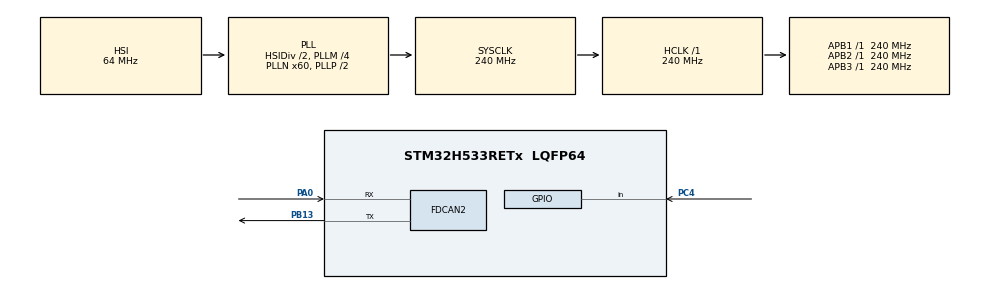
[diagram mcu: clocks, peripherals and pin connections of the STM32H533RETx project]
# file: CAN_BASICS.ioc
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BOOTPATH.BootPathName=LEGACY
BOOTPATH.UserSelectedBootPath=LEGACY
CORTEX_M33_NS.userName=CORTEX_M33
FDCAN2.CalculateBaudRateNominal=1000000
FDCAN2.CalculateTimeBitNominal=1000
FDCAN2.CalculateTimeQuantumNominal=100.0
FDCAN2.DataSyncJumpWidth=9
FDCAN2.DataTimeSeg1=10
FDCAN2.DataTimeSeg2=9
FDCAN2.FrameFormat=FDCAN_FRAME_FD_BRS
FDCAN2.NominalPrescaler=4
FDCAN2.NominalSyncJumpWidth=2
FDCAN2.NominalTimeSeg1=7
FDCAN2.NominalTimeSeg2=2
Mcu.Family=STM32H5
Mcu.Name=STM32H533RETx
Mcu.Package=LQFP64
NVIC.FDCAN2_IT0_IRQn=true\:0\:0\:false\:false\:true\:true\:true\:true
NVIC.PriorityGroup=NVIC_PRIORITYGROUP_4
PA0.Mode=FDCAN_Activate
PA0.Signal=FDCAN2_RX
PA13(JTMS/SWDIO).GPIO_Label=SWDIO
PA13(JTMS/SWDIO).Signal=DEBUG_JTMS-SWDIO
PA14(JTCK/SWCLK).GPIO_Label=SWCLK
PA14(JTCK/SWCLK).Signal=DEBUG_JTCK-SWCLK
PA15(JTDI).GPIO_Label=JTDI
PA15(JTDI).Signal=DEBUG_JTDI
PB13.Mode=FDCAN_Activate
PB13.Signal=FDCAN2_TX
PB3(JTDO/TRACESWO).GPIO_Label=SWO
PB3(JTDO/TRACESWO).Signal=DEBUG_JTDO-SWO
PC4.Signal=GPIO_Input
ProjectManager.HeapSize=0x200
ProjectManager.StackSize=0x400
ProjectManager.TargetToolchain=STM32CubeIDE
RCC.ADCFreq_Value=240000000
RCC.AHBFreq_Value=240000000
RCC.APB1Freq_Value=240000000
RCC.APB1TimFreq_Value=240000000
RCC.APB2Freq_Value=240000000
RCC.APB2TimFreq_Value=240000000
RCC.APB3Freq_Value=240000000
RCC.CSI_VALUE=4000000
RCC.CortexFreq_Value=240000000
RCC.EPOD_VALUE=32000000
RCC.FDCANClockSelection=RCC_FDCANCLKSOURCE_PLL1Q
RCC.HCLKFreq_Value=240000000
RCC.HSE_VALUE=25000000
RCC.HSI48_VALUE=48000000
RCC.HSI_VALUE=64000000
RCC.LSE_VALUE=32768
RCC.LSIRC_VALUE=32000
RCC.PLL1Q=12
RCC.PLLFRACN=0
RCC.PLLM=4
RCC.PLLN=60
RCC.PLLSourceVirtual=RCC_PLL1_SOURCE_HSI
RCC.SYSCLKFreq_VALUE=240000000
RCC.SYSCLKSource=RCC_SYSCLKSOURCE_PLLCLK
RCC.USBFreq_Value=48000000
RCC.VCOOutputFreq_Value=480000000
VP_BOOTPATH_VS_BOOTPATH.Mode=BP_Activate
VP_CORTEX_M33_NS_VS_Hclk.Mode=Hclk_Mode
VP_MEMORYMAP_VS_MEMORYMAP.Mode=CurAppReg
VP_PWR_VS_LPOM.Mode=PowerOptimisation
VP_PWR_VS_SECSignals.Mode=Security/Privilege
board=NUCLEO-H533RE

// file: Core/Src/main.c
/* USER CODE BEGIN Header */
/**
 ******************************************************************************
 * @file           : main.c
 * @brief          : Main program body
 ******************************************************************************
 * @attention
 *
 * Copyright (c) 2025 STMicroelectronics.
 * All rights reserved.
 *
 * This software is licensed under terms that can be found in the LICENSE file
 * in the root directory of this software component.
 * If no LICENSE file comes with this software, it is provided AS-IS.
 *
 ******************************************************************************
 */
/* USER CODE END Header */
#include "main.h"

/* USER CODE BEGIN Includes */
#include "string.h"
/* USER CODE END Includes */

FDCAN_HandleTypeDef hfdcan2;

/* USER CODE BEGIN PV */
FDCAN_TxHeaderTypeDef TxHeader;
FDCAN_RxHeaderTypeDef RxHeader;
uint8_t txMessageData[64];
uint8_t rxMessageData[64];
uint32_t messageID;
int receivedFrame = 0;
enum Message {
	VCUMaybe, VCUERROR1, VCUREADY
};
/* USER CODE END PV */

void SystemClock_Config(void);
static void MX_GPIO_Init(void);
static void MX_FDCAN2_Init(void);
/* USER CODE BEGIN PFP */
void startupFDCAN(FDCAN_HandleTypeDef *hfdcan, FDCAN_TxHeaderTypeDef *tx_header,
		void (*err_handler)(void));
/* USER CODE END PFP */

int main(void)
{

  /* MCU Configuration--------------------------------------------------------*/

  /* Reset of all peripherals, Initializes the Flash interface and the Systick. */
  HAL_Init();

  /* Configure the system clock */
  SystemClock_Config();

  /* Initialize all configured peripherals */
  MX_GPIO_Init();
  MX_FDCAN2_Init();
  /* USER CODE BEGIN 2 */
  startupFDCAN(&hfdcan2, &TxHeader, &Error_Handler);
  const char msgdata[] = "hello sebastian!";
  /* USER CODE END 2 */

  /* Infinite loop */
	while (1) {

    /* USER CODE BEGIN 3 */
		TxHeader.Identifier = 0x000;
		TxHeader.DataLength = FDCAN_DLC_BYTES_16;
		memcpy(txMessageData, msgdata, sizeof(msgdata) - 1);
		HAL_StatusTypeDef status = HAL_FDCAN_AddMessageToTxFifoQ(&hfdcan2,
				&TxHeader, txMessageData);
		if (status != HAL_OK) {
			Error_Handler();
		}
		HAL_Delay(10);

	}
  /* USER CODE END 3 */
}

void SystemClock_Config(void)
{
  RCC_OscInitTypeDef RCC_OscInitStruct = {0};
  RCC_ClkInitTypeDef RCC_ClkInitStruct = {0};

  /** Configure the main internal regulator output voltage
  */
  __HAL_PWR_VOLTAGESCALING_CONFIG(PWR_REGULATOR_VOLTAGE_SCALE0);

  while(!__HAL_PWR_GET_FLAG(PWR_FLAG_VOSRDY)) {}

  /** Initializes the RCC Oscillators according to the specified parameters
  * in the RCC_OscInitTypeDef structure.
  */
  RCC_OscInitStruct.OscillatorType = RCC_OSCILLATORTYPE_HSI;
  RCC_OscInitStruct.HSIState = RCC_HSI_ON;
  RCC_OscInitStruct.HSIDiv = RCC_HSI_DIV2;
  RCC_OscInitStruct.HSICalibrationValue = RCC_HSICALIBRATION_DEFAULT;
  RCC_OscInitStruct.PLL.PLLState = RCC_PLL_ON;
  RCC_OscInitStruct.PLL.PLLSource = RCC_PLL1_SOURCE_HSI;
  RCC_OscInitStruct.PLL.PLLM = 4;
  RCC_OscInitStruct.PLL.PLLN = 60;
  RCC_OscInitStruct.PLL.PLLP = 2;
  RCC_OscInitStruct.PLL.PLLQ = 12;
  RCC_OscInitStruct.PLL.PLLR = 2;
  RCC_OscInitStruct.PLL.PLLRGE = RCC_PLL1_VCIRANGE_3;
  RCC_OscInitStruct.PLL.PLLVCOSEL = RCC_PLL1_VCORANGE_WIDE;
  RCC_OscInitStruct.PLL.PLLFRACN = 0;
  if (HAL_RCC_OscConfig(&RCC_OscInitStruct) != HAL_OK)
  {
    Error_Handler();
  }

  /** Initializes the CPU, AHB and APB buses clocks
  */
  RCC_ClkInitStruct.ClockType = RCC_CLOCKTYPE_HCLK|RCC_CLOCKTYPE_SYSCLK
                              |RCC_CLOCKTYPE_PCLK1|RCC_CLOCKTYPE_PCLK2
                              |RCC_CLOCKTYPE_PCLK3;
  RCC_ClkInitStruct.SYSCLKSource = RCC_SYSCLKSOURCE_PLLCLK;
  RCC_ClkInitStruct.AHBCLKDivider = RCC_SYSCLK_DIV1;
  RCC_ClkInitStruct.APB1CLKDivider = RCC_HCLK_DIV1;
  RCC_ClkInitStruct.APB2CLKDivider = RCC_HCLK_DIV1;
  RCC_ClkInitStruct.APB3CLKDivider = RCC_HCLK_DIV1;

  if (HAL_RCC_ClockConfig(&RCC_ClkInitStruct, FLASH_LATENCY_5) != HAL_OK)
  {
    Error_Handler();
  }

  /** Configure the programming delay
  */
  __HAL_FLASH_SET_PROGRAM_DELAY(FLASH_PROGRAMMING_DELAY_2);
}

static void MX_FDCAN2_Init(void)
{

  hfdcan2.Instance = FDCAN2;
  hfdcan2.Init.ClockDivider = FDCAN_CLOCK_DIV1;
  hfdcan2.Init.FrameFormat = FDCAN_FRAME_FD_BRS;
  hfdcan2.Init.Mode = FDCAN_MODE_NORMAL;
  hfdcan2.Init.AutoRetransmission = DISABLE;
  hfdcan2.Init.TransmitPause = DISABLE;
  hfdcan2.Init.ProtocolException = DISABLE;
  hfdcan2.Init.NominalPrescaler = 4;
  hfdcan2.Init.NominalSyncJumpWidth = 2;
  hfdcan2.Init.NominalTimeSeg1 = 7;
  hfdcan2.Init.NominalTimeSeg2 = 2;
  hfdcan2.Init.DataPrescaler = 1;
  hfdcan2.Init.DataSyncJumpWidth = 9;
  hfdcan2.Init.DataTimeSeg1 = 10;
  hfdcan2.Init.DataTimeSeg2 = 9;
  hfdcan2.Init.StdFiltersNbr = 0;
  hfdcan2.Init.ExtFiltersNbr = 0;
  hfdcan2.Init.TxFifoQueueMode = FDCAN_TX_FIFO_OPERATION;
  if (HAL_FDCAN_Init(&hfdcan2) != HAL_OK)
  {
    Error_Handler();
  }

}

static void MX_GPIO_Init(void)
{
  GPIO_InitTypeDef GPIO_InitStruct = {0};

  /* GPIO Ports Clock Enable */
  __HAL_RCC_GPIOA_CLK_ENABLE();
  __HAL_RCC_GPIOC_CLK_ENABLE();
  __HAL_RCC_GPIOB_CLK_ENABLE();

  /*Configure GPIO pin : PC4 */
  GPIO_InitStruct.Pin = GPIO_PIN_4;
  GPIO_InitStruct.Mode = GPIO_MODE_INPUT;
  GPIO_InitStruct.Pull = GPIO_NOPULL;
  HAL_GPIO_Init(GPIOC, &GPIO_InitStruct);

}

/* USER CODE BEGIN 4 */

void configureFDCANTransmissionHeader(FDCAN_TxHeaderTypeDef *tx_header) {
	tx_header->IdType = FDCAN_STANDARD_ID;
	tx_header->TxFrameType = FDCAN_DATA_FRAME;
	tx_header->DataLength = FDCAN_DLC_BYTES_16;
	tx_header->ErrorStateIndicator = FDCAN_ESI_ACTIVE;
	tx_header->BitRateSwitch = FDCAN_BRS_ON;
	tx_header->FDFormat = FDCAN_FD_CAN;
	tx_header->TxEventFifoControl = FDCAN_NO_TX_EVENTS;
	tx_header->MessageMarker = 0;
}

void startupFDCAN(FDCAN_HandleTypeDef *hfdcan, FDCAN_TxHeaderTypeDef *tx_header,
		void (*err_handler)(void)) {
	HAL_StatusTypeDef hal_status;

	if (HAL_FDCAN_GetState(hfdcan) != HAL_FDCAN_STATE_READY) {
		err_handler();  // startupFDCAN called before hfdcan initialized.
	}

	// Enable CAN transceiver & interrupts
	//stby_pin->digitalWrite(false);  // Enable the transceiver
	hal_status = HAL_FDCAN_Start(hfdcan);
	if (hal_status != HAL_OK) {
		err_handler();
	}

	// Activate RX interrupts
	hal_status = HAL_FDCAN_ActivateNotification(hfdcan,
	FDCAN_IT_RX_FIFO0_NEW_MESSAGE, 0);
	if (hal_status != HAL_OK) {
		err_handler();
	}

	configureFDCANTransmissionHeader(tx_header);

	if (HAL_FDCAN_GetState(hfdcan) == HAL_FDCAN_STATE_ERROR) {
		err_handler(); // Make sure we're not in an error state
	}
}

void HAL_FDCAN_RxFifo0Callback(FDCAN_HandleTypeDef *hfdcan, uint32_t RxFifo0ITs) {
	if ((RxFifo0ITs & FDCAN_IT_RX_FIFO0_NEW_MESSAGE) != RESET) {
		/* Retrieve RX messages from RX FIFO0 */
		if (HAL_FDCAN_GetRxMessage(hfdcan, FDCAN_RX_FIFO0, &RxHeader,
				rxMessageData) != HAL_OK) {
			/* Reception Error */
			Error_Handler();
		}
		receivedFrame = 1;
		if (HAL_FDCAN_ActivateNotification(hfdcan,
		FDCAN_IT_RX_FIFO0_NEW_MESSAGE, 0) != HAL_OK) {
			/* Notification Error */
			Error_Handler();
		}
	}
}

/* USER CODE END 4 */

void Error_Handler(void)
{
	__disable_irq();
	while (1) {
	}
}
